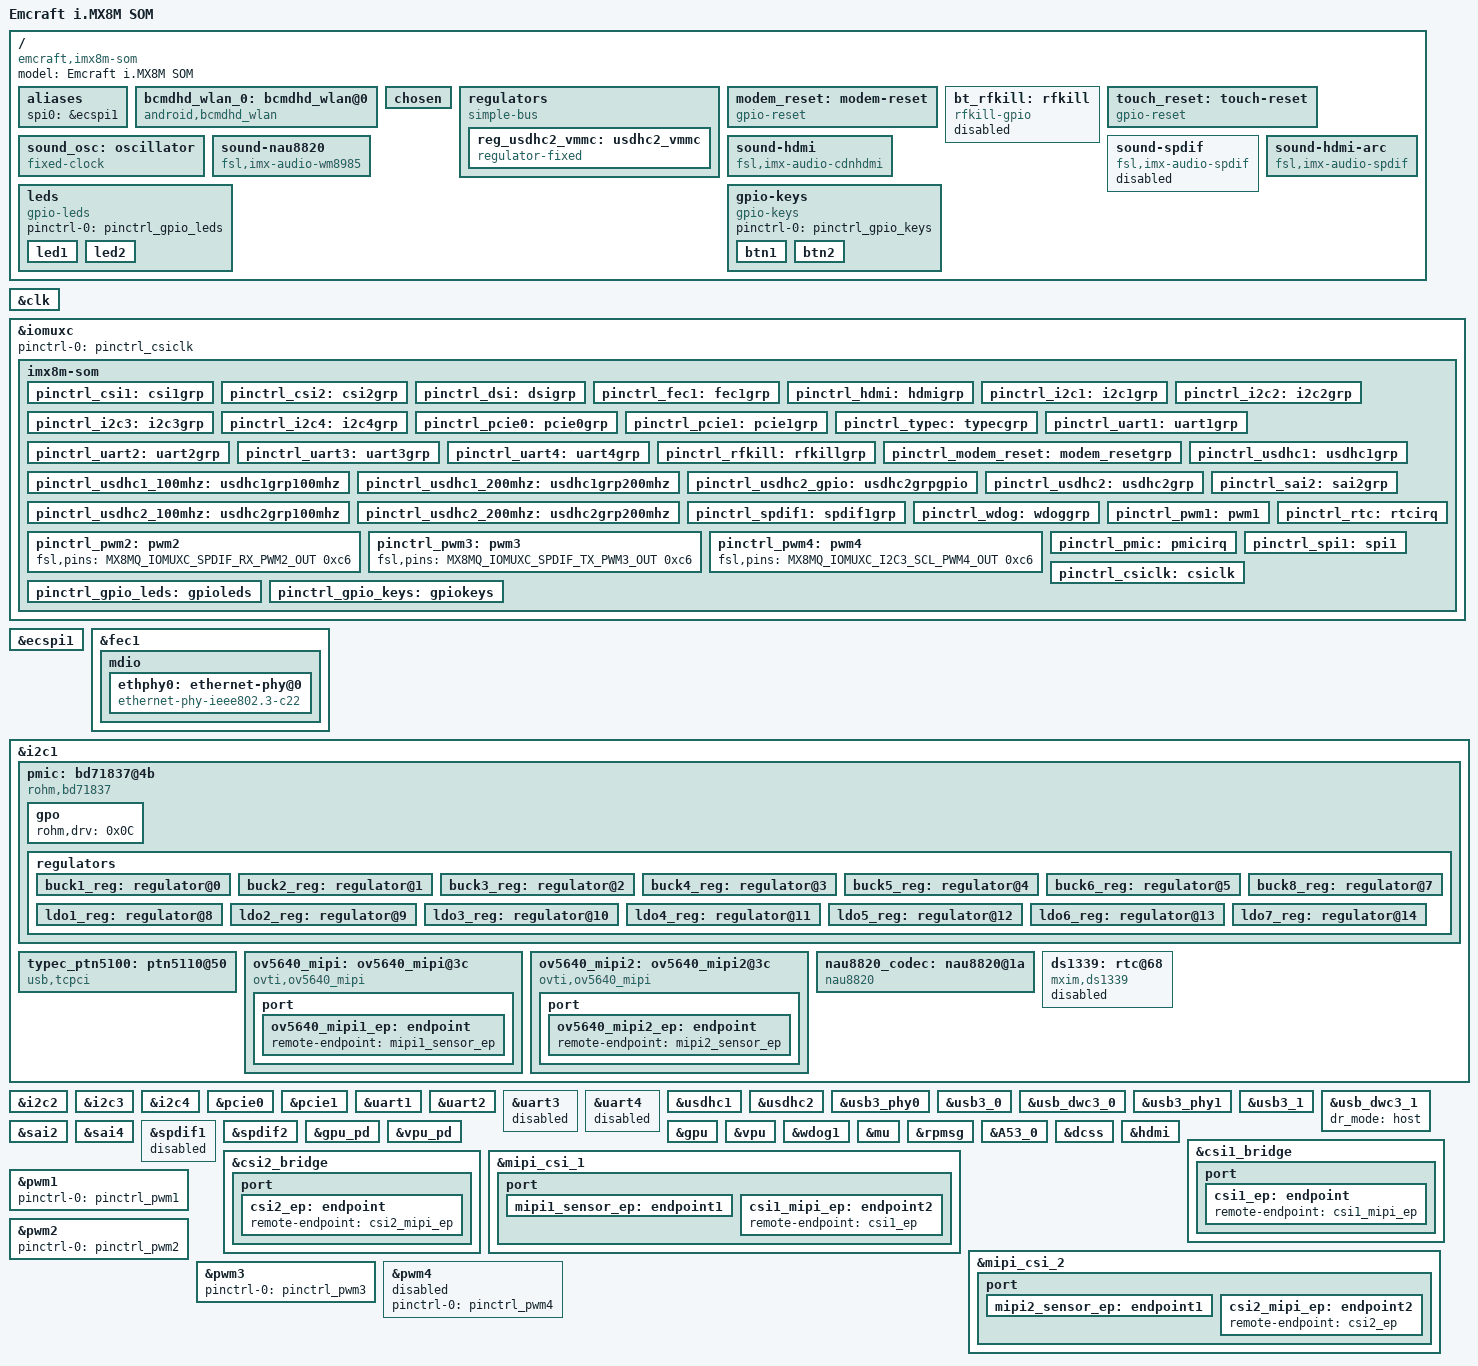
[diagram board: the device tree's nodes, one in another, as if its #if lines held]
/*
 * Copyright 2017 NXP
 *
 * This program is free software; you can redistribute it and/or
 * modify it under the terms of the GNU General Public License
 * as published by the Free Software Foundation; either version 2
 * of the License, or (at your option) any later version.
 *
 * This program is distributed in the hope that it will be useful,
 * but WITHOUT ANY WARRANTY; without even the implied warranty of
 * MERCHANTABILITY or FITNESS FOR A PARTICULAR PURPOSE.  See the
 * GNU General Public License for more details.
 */

/dts-v1/;

/*
 * Define this to support IMX8M-SOM-BSB with external PHY clock
 * #define PHY_USE_EXT25MHZ
 */

/*
 * Define this to enable i2c3 channel instead of pwm4 on IMX8M-SOM-BSB
 * #define I2C3_ENABLE
 */
#define I2C3_ENABLE

/*
 * Define this to enable camera on CSI2 channel instead of CSI1
 * #define CSI2_CAM_ENABLE
 */

#include "freescale/fsl-imx8mq.dtsi"

/ {
	model = "Emcraft i.MX8M SOM";
	compatible = "emcraft,imx8m-som", "fsl,imx8mq";

	aliases {
	    spi0 = &ecspi1;
	};

	bcmdhd_wlan_0: bcmdhd_wlan@0 {
		compatible = "android,bcmdhd_wlan";
		bcmdhd_fw = "/lib/firmware/bcm/1CX_BCM4356/fw_bcmdhd.bin";
		bcmdhd_nv = "/lib/firmware/bcm/1CX_BCM4356/bcmdhd.cal";
	};

	chosen {
		bootargs = "console=ttymxc0,115200 earlycon=ec_imx6q,0x30860000,115200";
		stdout-path = &uart1;
	};

	regulators {
		compatible = "simple-bus";
		#address-cells = <1>;
		#size-cells = <0>;

		reg_usdhc2_vmmc: usdhc2_vmmc {
			compatible = "regulator-fixed";
			regulator-name = "VSD_3V3";
			regulator-min-microvolt = <3300000>;
			regulator-max-microvolt = <3300000>;
			gpio = <&gpio2 19 GPIO_ACTIVE_HIGH>;
			enable-active-high;
		};
	};

	modem_reset: modem-reset {
		compatible = "gpio-reset";
		pinctrl-names = "default";
		pinctrl-0 = <&pinctrl_modem_reset>;
		reset-gpios = <&gpio3 6 GPIO_ACTIVE_LOW>;
		reset-delay-us = <2000>;
		reset-post-delay-ms = <40>;
		#reset-cells = <0>;
		status = "okay";
	};

	bt_rfkill: rfkill {
		compatible = "rfkill-gpio";
		pinctrl-names = "default";
		pinctrl-0 = <&pinctrl_rfkill>;
		type = "bluetooth";
		shutdown-gpios = <&gpio3 3 GPIO_ACTIVE_HIGH>;
		status = "disabled";
	};

	touch_reset: touch-reset {
		compatible = "gpio-reset";
		reset-gpios = <&gpio3 9 GPIO_ACTIVE_LOW>;
		reset-delay-us = <10000>;
		#reset-cells = <0>;
	};

	sound_osc: oscillator {
		compatible = "fixed-clock";
		#clock-cells = <1>;
		clock-frequency  = <12000000>;
		clock-output-names = "sound_osc";
	};

	sound-nau8820 {
		compatible = "fsl,imx-audio-wm8985";
		model = "nau8820-audio";
		audio-cpu = <&sai2>;
		audio-codec = <&nau8820_codec>;
	};

	sound-hdmi {
		compatible = "fsl,imx-audio-cdnhdmi";
		model = "imx-audio-hdmi";
		audio-cpu = <&sai4>;
		protocol = <1>;
	};

	sound-spdif {
		compatible = "fsl,imx-audio-spdif";
		model = "imx-spdif";
		spdif-controller = <&spdif1>;
		spdif-out;
		spdif-in;
		status = "disabled";
	};

	sound-hdmi-arc {
		compatible = "fsl,imx-audio-spdif";
		model = "imx-hdmi-arc";
		spdif-controller = <&spdif2>;
		spdif-in;
	};

	leds {
		compatible = "gpio-leds";
		pinctrl-names = "default";
		pinctrl-0 = <&pinctrl_gpio_leds>;
		status = "okay";

		led1 {
			label = "LED 1";
			gpios = <&gpio3 19 GPIO_ACTIVE_HIGH>;
			default-state = "off";
		};
		led2 {
			label = "LED 2";
			gpios = <&gpio1 13 GPIO_ACTIVE_HIGH>;
			default-state = "off";
		};
	};

	gpio-keys {
		compatible = "gpio-keys";
		pinctrl-names = "default";
		pinctrl-0 = <&pinctrl_gpio_keys>;

		btn1 {
			label = "BTN 1";
			gpios = <&gpio4 21 GPIO_ACTIVE_LOW>;
			gpio-key,wakeup;
			linux,code = <KEY_VOLUMEUP>;
		};
		btn2 {
			label = "BTN 2";
			gpios = <&gpio4 22 GPIO_ACTIVE_LOW>;
			gpio-key,wakeup;
			linux,code = <KEY_VOLUMEDOWN>;
		};
	};
};

&clk {
	assigned-clocks = <&clk IMX8MQ_AUDIO_PLL1>;
	assigned-clock-rates = <786432000>;
};

&iomuxc {
	pinctrl-names = "default";
	pinctrl-0 = <&pinctrl_csiclk>;

	imx8m-som {
		pinctrl_csi1: csi1grp {
			fsl,pins = <
				MX8MQ_IOMUXC_GPIO1_IO07_GPIO1_IO7		0x19
			>;
		};
		pinctrl_csi2: csi2grp {
			fsl,pins = <
				MX8MQ_IOMUXC_GPIO1_IO05_GPIO1_IO5		0x19
			>;
		};

		pinctrl_dsi: dsigrp {
			fsl,pins = <
				MX8MQ_IOMUXC_NAND_DATA07_GPIO3_IO13	0x16
			>;
		};

		pinctrl_fec1: fec1grp {
			fsl,pins = <
				MX8MQ_IOMUXC_ENET_MDC_ENET1_MDC		0x3
				MX8MQ_IOMUXC_ENET_MDIO_ENET1_MDIO	0x23
				MX8MQ_IOMUXC_ENET_TD3_ENET1_RGMII_TD3	0x1f
				MX8MQ_IOMUXC_ENET_TD2_ENET1_RGMII_TD2	0x1f
				MX8MQ_IOMUXC_ENET_TD1_ENET1_RGMII_TD1	0x1f
				MX8MQ_IOMUXC_ENET_TD0_ENET1_RGMII_TD0	0x1f
				MX8MQ_IOMUXC_ENET_RD3_ENET1_RGMII_RD3	0x91
				MX8MQ_IOMUXC_ENET_RD2_ENET1_RGMII_RD2	0x91
				MX8MQ_IOMUXC_ENET_RD1_ENET1_RGMII_RD1	0x91
				MX8MQ_IOMUXC_ENET_RD0_ENET1_RGMII_RD0	0x91
				MX8MQ_IOMUXC_ENET_TXC_ENET1_RGMII_TXC	0x1f
				MX8MQ_IOMUXC_ENET_RXC_ENET1_RGMII_RXC	0x91
				MX8MQ_IOMUXC_ENET_RX_CTL_ENET1_RGMII_RX_CTL	0x91
				MX8MQ_IOMUXC_ENET_TX_CTL_ENET1_RGMII_TX_CTL	0x1f
				MX8MQ_IOMUXC_GPIO1_IO09_GPIO1_IO9	0x19
				MX8MQ_IOMUXC_GPIO1_IO15_CCMSRCGPCMIX_CLKO2      0x1f
			>;
		};

		pinctrl_hdmi: hdmigrp {
			fsl,pins = <
				MX8MQ_IOMUXC_SAI3_MCLK_GPIO5_IO2	0x16
			>;
		};

		pinctrl_i2c1: i2c1grp {
			fsl,pins = <
				MX8MQ_IOMUXC_I2C1_SCL_I2C1_SCL			0x4000007f
				MX8MQ_IOMUXC_I2C1_SDA_I2C1_SDA			0x4000007f
			>;
		};

		pinctrl_i2c2: i2c2grp {
			fsl,pins = <
				MX8MQ_IOMUXC_I2C2_SCL_I2C2_SCL			0x4000007f
				MX8MQ_IOMUXC_I2C2_SDA_I2C2_SDA			0x4000007f
			>;
		};

		pinctrl_i2c3: i2c3grp {
			fsl,pins = <
				MX8MQ_IOMUXC_I2C3_SCL_I2C3_SCL			0x4000007f
				MX8MQ_IOMUXC_I2C3_SDA_I2C3_SDA			0x4000007f
				MX8MQ_IOMUXC_NAND_DATA02_GPIO3_IO8		0x17059	/* TOUCH INT */
				MX8MQ_IOMUXC_NAND_DATA03_GPIO3_IO9		0x16	/* TOUCH RST */
			>;
		};

		pinctrl_i2c4: i2c4grp {
			fsl,pins = <
				MX8MQ_IOMUXC_I2C4_SCL_I2C4_SCL			0x4000007f
				MX8MQ_IOMUXC_I2C4_SDA_I2C4_SDA			0x4000007f
			>;
		};


		pinctrl_pcie0: pcie0grp {
			fsl,pins = <
				MX8MQ_IOMUXC_NAND_RE_B_GPIO3_IO15	0x16
				MX8MQ_IOMUXC_NAND_DATA05_GPIO3_IO11	0x16
				MX8MQ_IOMUXC_NAND_DATA04_GPIO3_IO10	0x16
			>;
		};

		pinctrl_pcie1: pcie1grp {
			fsl,pins = <
				MX8MQ_IOMUXC_NAND_WP_B_GPIO3_IO18	0x16
				MX8MQ_IOMUXC_NAND_CLE_GPIO3_IO5	0x16
				MX8MQ_IOMUXC_NAND_WE_B_GPIO3_IO17	0x16
			>;
		};


		pinctrl_typec: typecgrp {
			fsl,pins = <
				MX8MQ_IOMUXC_NAND_DATA06_GPIO3_IO12	0x16
				MX8MQ_IOMUXC_NAND_CE0_B_GPIO3_IO1	0x17059
			>;
		};

		pinctrl_uart1: uart1grp {
			fsl,pins = <
				MX8MQ_IOMUXC_UART1_RXD_UART1_DCE_RX		0x49
				MX8MQ_IOMUXC_UART1_TXD_UART1_DCE_TX		0x49
			>;
		};

		pinctrl_uart2: uart2grp {
			fsl,pins = <
				MX8MQ_IOMUXC_UART2_TXD_UART2_DCE_TX		0x49
				MX8MQ_IOMUXC_UART2_RXD_UART2_DCE_RX		0x49
				MX8MQ_IOMUXC_UART4_RXD_UART2_DCE_CTS_B		0x49
				MX8MQ_IOMUXC_UART4_TXD_UART2_DCE_RTS_B		0x49
			>;
		};

		pinctrl_uart3: uart3grp {
			fsl,pins = <
				MX8MQ_IOMUXC_UART3_RXD_UART3_DCE_RX		0x49
				MX8MQ_IOMUXC_UART3_TXD_UART3_DCE_TX		0x49
			>;
		};

		pinctrl_uart4: uart4grp {
			fsl,pins = <
				MX8MQ_IOMUXC_ECSPI2_SCLK_UART4_DCE_RX		0x49
				MX8MQ_IOMUXC_ECSPI2_MOSI_UART4_DCE_TX		0x49
				MX8MQ_IOMUXC_ECSPI2_MISO_UART4_DCE_CTS_B	0x49
				MX8MQ_IOMUXC_ECSPI2_SS0_UART4_DCE_RTS_B		0x49
				MX8MQ_IOMUXC_GPIO1_IO00_ANAMIX_REF_CLK_32K	0x49
			>;
		};

		pinctrl_rfkill: rfkillgrp {
			fsl,pins = <
				/* BT_RF_KILL */
				MX8MQ_IOMUXC_NAND_CE2_B_GPIO3_IO3		0x19
			>;
		};

		pinctrl_modem_reset: modem_resetgrp {
			fsl,pins = <
				/* BT_REG_ON */
				MX8MQ_IOMUXC_NAND_DATA00_GPIO3_IO6		0x19
			>;
		};

		pinctrl_usdhc1: usdhc1grp {
			fsl,pins = <
				MX8MQ_IOMUXC_SD1_CLK_USDHC1_CLK			0x83
				MX8MQ_IOMUXC_SD1_CMD_USDHC1_CMD			0xc3
				MX8MQ_IOMUXC_SD1_DATA0_USDHC1_DATA0		0xc3
				MX8MQ_IOMUXC_SD1_DATA1_USDHC1_DATA1		0xc3
				MX8MQ_IOMUXC_SD1_DATA2_USDHC1_DATA2		0xc3
				MX8MQ_IOMUXC_SD1_DATA3_USDHC1_DATA3		0xc3
				MX8MQ_IOMUXC_SD1_DATA4_USDHC1_DATA4		0xc3
				MX8MQ_IOMUXC_SD1_DATA5_USDHC1_DATA5		0xc3
				MX8MQ_IOMUXC_SD1_DATA6_USDHC1_DATA6		0xc3
				MX8MQ_IOMUXC_SD1_DATA7_USDHC1_DATA7		0xc3
				MX8MQ_IOMUXC_SD1_STROBE_USDHC1_STROBE		0x83
				MX8MQ_IOMUXC_SD1_RESET_B_USDHC1_RESET_B		0xc1
			>;
		};

		pinctrl_usdhc1_100mhz: usdhc1grp100mhz {
			fsl,pins = <
				MX8MQ_IOMUXC_SD1_CLK_USDHC1_CLK			0x85
				MX8MQ_IOMUXC_SD1_CMD_USDHC1_CMD			0xc5
				MX8MQ_IOMUXC_SD1_DATA0_USDHC1_DATA0		0xc5
				MX8MQ_IOMUXC_SD1_DATA1_USDHC1_DATA1		0xc5
				MX8MQ_IOMUXC_SD1_DATA2_USDHC1_DATA2		0xc5
				MX8MQ_IOMUXC_SD1_DATA3_USDHC1_DATA3		0xc5
				MX8MQ_IOMUXC_SD1_DATA4_USDHC1_DATA4		0xc5
				MX8MQ_IOMUXC_SD1_DATA5_USDHC1_DATA5		0xc5
				MX8MQ_IOMUXC_SD1_DATA6_USDHC1_DATA6		0xc5
				MX8MQ_IOMUXC_SD1_DATA7_USDHC1_DATA7		0xc5
				MX8MQ_IOMUXC_SD1_STROBE_USDHC1_STROBE		0x85
				MX8MQ_IOMUXC_SD1_RESET_B_USDHC1_RESET_B		0xc1
			>;
		};

		pinctrl_usdhc1_200mhz: usdhc1grp200mhz {
			fsl,pins = <
				MX8MQ_IOMUXC_SD1_CLK_USDHC1_CLK			0x87
				MX8MQ_IOMUXC_SD1_CMD_USDHC1_CMD			0xc7
				MX8MQ_IOMUXC_SD1_DATA0_USDHC1_DATA0		0xc7
				MX8MQ_IOMUXC_SD1_DATA1_USDHC1_DATA1		0xc7
				MX8MQ_IOMUXC_SD1_DATA2_USDHC1_DATA2		0xc7
				MX8MQ_IOMUXC_SD1_DATA3_USDHC1_DATA3		0xc7
				MX8MQ_IOMUXC_SD1_DATA4_USDHC1_DATA4		0xc7
				MX8MQ_IOMUXC_SD1_DATA5_USDHC1_DATA5		0xc7
				MX8MQ_IOMUXC_SD1_DATA6_USDHC1_DATA6		0xc7
				MX8MQ_IOMUXC_SD1_DATA7_USDHC1_DATA7		0xc7
				MX8MQ_IOMUXC_SD1_STROBE_USDHC1_STROBE		0x87
				MX8MQ_IOMUXC_SD1_RESET_B_USDHC1_RESET_B		0xc1
			>;
		};

		pinctrl_usdhc2_gpio: usdhc2grpgpio {
			fsl,pins = <
				MX8MQ_IOMUXC_SD2_CD_B_GPIO2_IO12	0x41
				MX8MQ_IOMUXC_SD2_RESET_B_GPIO2_IO19	0x41
			>;
		};

		pinctrl_usdhc2: usdhc2grp {
			fsl,pins = <
				MX8MQ_IOMUXC_SD2_CLK_USDHC2_CLK			0x83
				MX8MQ_IOMUXC_SD2_CMD_USDHC2_CMD			0xc3
				MX8MQ_IOMUXC_SD2_DATA0_USDHC2_DATA0		0xc3
				MX8MQ_IOMUXC_SD2_DATA1_USDHC2_DATA1		0xc3
				MX8MQ_IOMUXC_SD2_DATA2_USDHC2_DATA2		0xc3
				MX8MQ_IOMUXC_SD2_DATA3_USDHC2_DATA3		0xc3
				MX8MQ_IOMUXC_GPIO1_IO04_USDHC2_VSELECT		0xc1
			>;
		};

		pinctrl_usdhc2_100mhz: usdhc2grp100mhz {
			fsl,pins = <
				MX8MQ_IOMUXC_SD2_CLK_USDHC2_CLK			0x85
				MX8MQ_IOMUXC_SD2_CMD_USDHC2_CMD			0xc5
				MX8MQ_IOMUXC_SD2_DATA0_USDHC2_DATA0		0xc5
				MX8MQ_IOMUXC_SD2_DATA1_USDHC2_DATA1		0xc5
				MX8MQ_IOMUXC_SD2_DATA2_USDHC2_DATA2		0xc5
				MX8MQ_IOMUXC_SD2_DATA3_USDHC2_DATA3		0xc5
				MX8MQ_IOMUXC_GPIO1_IO04_USDHC2_VSELECT		0xc1
			>;
		};

		pinctrl_usdhc2_200mhz: usdhc2grp200mhz {
			fsl,pins = <
				MX8MQ_IOMUXC_SD2_CLK_USDHC2_CLK			0x87
				MX8MQ_IOMUXC_SD2_CMD_USDHC2_CMD			0xc7
				MX8MQ_IOMUXC_SD2_DATA0_USDHC2_DATA0		0xc7
				MX8MQ_IOMUXC_SD2_DATA1_USDHC2_DATA1		0xc7
				MX8MQ_IOMUXC_SD2_DATA2_USDHC2_DATA2		0xc7
				MX8MQ_IOMUXC_SD2_DATA3_USDHC2_DATA3		0xc7
				MX8MQ_IOMUXC_GPIO1_IO04_USDHC2_VSELECT		0xc1
			>;
		};

		pinctrl_sai2: sai2grp {
			fsl,pins = <
				MX8MQ_IOMUXC_SAI2_TXFS_SAI2_TX_SYNC	0xd6
				MX8MQ_IOMUXC_SAI2_TXC_SAI2_TX_BCLK	0xd6
				MX8MQ_IOMUXC_SAI2_TXD0_SAI2_TX_DATA0	0xd6
				MX8MQ_IOMUXC_SAI2_RXD0_SAI2_RX_DATA0	0xd6
			>;
		};

		pinctrl_spdif1: spdif1grp {
			fsl,pins = <
				MX8MQ_IOMUXC_SPDIF_TX_SPDIF1_OUT	0xd6
				MX8MQ_IOMUXC_SPDIF_RX_SPDIF1_IN		0xd6
			>;
		};

		pinctrl_wdog: wdoggrp {
			fsl,pins = <
				MX8MQ_IOMUXC_GPIO1_IO02_WDOG1_WDOG_B 0xc6
			>;
		};

		pinctrl_pwm1: pwm1 {
			fsl,pins = <
				MX8MQ_IOMUXC_SPDIF_EXT_CLK_PWM1_OUT 0xc6
			>;
		};

		pinctrl_pwm2: pwm2 {
			fsl,pins = <
				MX8MQ_IOMUXC_SPDIF_RX_PWM2_OUT 0xc6
			>;
		};

		pinctrl_pwm3: pwm3 {
			fsl,pins = <
				MX8MQ_IOMUXC_SPDIF_TX_PWM3_OUT 0xc6
			>;
		};

		pinctrl_pwm4: pwm4 {
			fsl,pins = <
				MX8MQ_IOMUXC_I2C3_SCL_PWM4_OUT 0xc6
			>;
		};

		pinctrl_pmic: pmicirq {
			fsl,pins = <
				MX8MQ_IOMUXC_GPIO1_IO12_GPIO1_IO12	0x41 /*0x17059*/
			>;
		};

		pinctrl_rtc: rtcirq {
			fsl,pins = <
				MX8MQ_IOMUXC_SAI3_RXC_GPIO4_IO29	0xC6
			>;
		};

		pinctrl_spi1: spi1 {
			fsl,pins = <
				MX8MQ_IOMUXC_ECSPI1_SCLK_ECSPI1_SCLK	0x0f
				MX8MQ_IOMUXC_ECSPI1_MOSI_ECSPI1_MOSI	0x0f
				MX8MQ_IOMUXC_ECSPI1_MISO_ECSPI1_MISO	0x0f
				MX8MQ_IOMUXC_ECSPI1_SS0_GPIO5_IO9	0x09
				MX8MQ_IOMUXC_NAND_CE1_B_GPIO3_IO2	0x09
			>;
		};

		pinctrl_csiclk: csiclk {
			fsl,pins = <
				MX8MQ_IOMUXC_GPIO1_IO14_CCMSRCGPCMIX_CLKO1	0x59
			>;
		};

		pinctrl_gpio_leds: gpioleds {
			fsl,pins = <
				MX8MQ_IOMUXC_SAI5_RXFS_GPIO3_IO19	0x16
				MX8MQ_IOMUXC_GPIO1_IO13_GPIO1_IO13	0x16
			>;
		};

		pinctrl_gpio_keys: gpiokeys {
			fsl,pins = <
				MX8MQ_IOMUXC_SAI2_RXFS_GPIO4_IO21	0x16
				MX8MQ_IOMUXC_SAI2_RXC_GPIO4_IO22	0x16
			>;
		};
	};
};

&ecspi1 {
	pinctrl-names = "default";
	pinctrl-0 = <&pinctrl_spi1>;
	status = "okay";
	cs-gpios = <&gpio5 9 GPIO_ACTIVE_LOW>, <&gpio3 2 GPIO_ACTIVE_LOW>;
	#address-cells = <1>;
	#size-cells = <0>;
};

&fec1 {
	pinctrl-names = "default";
	pinctrl-0 = <&pinctrl_fec1>;
	phy-mode = "rgmii-id";
	phy-handle = <&ethphy0>;
	fsl,magic-packet;
	status = "okay";

#ifdef PHY_USE_EXT25MHZ
	/* Removed "enet_phy_out" */
	clock-names = "ipg", "ahb", "ptp",
		    "enet_clk_ref", "enet_out";
#endif
	mdio {
		#address-cells = <1>;
		#size-cells = <0>;

		ethphy0: ethernet-phy@0 {
			compatible = "ethernet-phy-ieee802.3-c22";
			reg = <1>;
			at803x,led-act-blind-workaround;
			at803x,eee-disabled;
		};
	};
};

&i2c1 {
	clock-frequency = <100000>;
	pinctrl-names = "default";
	pinctrl-0 = <&pinctrl_i2c1>;
	status = "okay";

	pmic: bd71837@4b {
		reg = <0x4b>;
		compatible = "rohm,bd71837";
		/* PMIC BD71837 PMIC_nINT GPIO1_IO12 */
		pinctrl-0 = <&pinctrl_pmic>;
		gpio_intr = <&gpio1 12 GPIO_ACTIVE_LOW>;

		bd71837,pmic-buck1-uses-i2c-dvs;
		bd71837,pmic-buck1-dvs-voltage = <900000>, <850000>, <800000>; /* VDD_SOC: Run-Idle-Suspend */
		bd71837,pmic-buck2-uses-i2c-dvs;
		bd71837,pmic-buck2-dvs-voltage = <1000000>, <900000>, <0>; /* VDD_ARM: Run-Idle */
		bd71837,pmic-buck3-uses-i2c-dvs;
		bd71837,pmic-buck3-dvs-voltage = <1000000>, <0>, <0>; /* VDD_GPU: Run */
		bd71837,pmic-buck4-uses-i2c-dvs;
		bd71837,pmic-buck4-dvs-voltage = <1000000>, <0>, <0>; /* VDD_VPU: Run */

		gpo {
			rohm,drv = <0x0C>;	/* 0b0000_1100 all gpos with cmos output mode */
		};

		regulators {
			#address-cells = <1>;
			#size-cells = <0>;

			buck1_reg: regulator@0 {
				reg = <0>;
				regulator-compatible = "buck1";
				regulator-min-microvolt = <700000>;
				regulator-max-microvolt = <1300000>;
				regulator-boot-on;
				regulator-always-on;
				regulator-ramp-delay = <1250>;
			};

			buck2_reg: regulator@1 {
				reg = <1>;
				regulator-compatible = "buck2";
				regulator-min-microvolt = <700000>;
				regulator-max-microvolt = <1300000>;
				regulator-boot-on;
				regulator-always-on;
				regulator-ramp-delay = <1250>;
			};

			buck3_reg: regulator@2 {
				reg = <2>;
				regulator-compatible = "buck3";
				regulator-min-microvolt = <700000>;
				regulator-max-microvolt = <1300000>;
				regulator-boot-on;
				regulator-always-on;
			};

			buck4_reg: regulator@3 {
				reg = <3>;
				regulator-compatible = "buck4";
				regulator-min-microvolt = <700000>;
				regulator-max-microvolt = <1300000>;
				regulator-boot-on;
				regulator-always-on;
			};

			buck5_reg: regulator@4 {
				reg = <4>;
				regulator-compatible = "buck5";
				regulator-min-microvolt = <700000>;
				regulator-max-microvolt = <1350000>;
				regulator-boot-on;
				regulator-always-on;
			};

			buck6_reg: regulator@5 {
				reg = <5>;
				regulator-compatible = "buck6";
				regulator-min-microvolt = <3000000>;
				regulator-max-microvolt = <3300000>;
				regulator-boot-on;
				regulator-always-on;
			};
#if 0
			buck7_reg: regulator@6 {
				reg = <6>;
				regulator-compatible = "buck7";
				regulator-min-microvolt = <1605000>;
				regulator-max-microvolt = <1995000>;
				regulator-boot-on;
				regulator-always-on;
			};
#endif
			buck8_reg: regulator@7 {
				reg = <7>;
				regulator-compatible = "buck8";
				regulator-min-microvolt = <800000>;
				regulator-max-microvolt = <1400000>;
				regulator-boot-on;
				regulator-always-on;
			};

			ldo1_reg: regulator@8 {
				reg = <8>;
				regulator-compatible = "ldo1";
				regulator-min-microvolt = <3000000>;
				regulator-max-microvolt = <3300000>;
				regulator-boot-on;
				regulator-always-on;
			};

			ldo2_reg: regulator@9 {
				reg = <9>;
				regulator-compatible = "ldo2";
				regulator-min-microvolt = <900000>;
				regulator-max-microvolt = <900000>;
				regulator-boot-on;
				regulator-always-on;
			};

			ldo3_reg: regulator@10 {
				reg = <10>;
				regulator-compatible = "ldo3";
				regulator-min-microvolt = <1800000>;
				regulator-max-microvolt = <3300000>;
				regulator-boot-on;
				regulator-always-on;
			};

			ldo4_reg: regulator@11 {
				reg = <11>;
				regulator-compatible = "ldo4";
				regulator-min-microvolt = <900000>;
				regulator-max-microvolt = <1800000>;
				regulator-boot-on;
				regulator-always-on;
			};

			ldo5_reg: regulator@12 {
				reg = <12>;
				regulator-compatible = "ldo5";
				regulator-min-microvolt = <1800000>;
				regulator-max-microvolt = <3300000>;
				regulator-boot-on;
				regulator-always-on;
			};

			ldo6_reg: regulator@13 {
				reg = <13>;
				regulator-compatible = "ldo6";
				regulator-min-microvolt = <900000>;
				regulator-max-microvolt = <1800000>;
				regulator-boot-on;
				regulator-always-on;
			};

			ldo7_reg: regulator@14 {
				reg = <14>;
				regulator-compatible = "ldo7";
				regulator-min-microvolt = <1800000>;
				regulator-max-microvolt = <3300000>;
				regulator-boot-on;
				regulator-always-on;
			};
		};
	};

	typec_ptn5100: ptn5110@50 {
		compatible = "usb,tcpci";
		pinctrl-names = "default";
		pinctrl-0 = <&pinctrl_typec>;
		reg = <0x52>;
		interrupt-parent = <&gpio3>;
		interrupts = <1 IRQ_TYPE_LEVEL_LOW>;
		ss-sel-gpios = <&gpio3 12 GPIO_ACTIVE_HIGH>;
		src-pdos = <0x380190c8>;
		snk-pdos = <0x380190c8 0x3802d0c8>;
		max-snk-mv = <9000>;
		max-snk-ma = <1000>;
		max-snk-mw = <9000>;
		op-snk-mw = <9000>;
		port-type = "drp";
		default-role = "sink";
	};

	ov5640_mipi: ov5640_mipi@3c {
		compatible = "ovti,ov5640_mipi";
		reg = <0x3c>;
#ifndef CSI2_CAM_ENABLE
		status = "okay";
#else
		status = "disabled";
#endif
		pinctrl-names = "default";
		pinctrl-0 = <&pinctrl_csi1>;
		clocks = <&clk IMX8MQ_CLK_CLKO1_DIV>;
		clock-names = "csi_mclk";
		assigned-clocks = <&clk IMX8MQ_CLK_CLKO1_SRC>,
				  <&clk IMX8MQ_CLK_CLKO1_DIV>;
		assigned-clock-parents = <&clk IMX8MQ_SYS1_PLL_200M>;
		assigned-clock-rates = <0>, <20000000>;
		csi_id = <0>;
		pwn-gpios = <&gpio1 7 GPIO_ACTIVE_LOW>;
		mclk = <20000000>;
		mclk_source = <0>;
		port {
			ov5640_mipi1_ep: endpoint {
				remote-endpoint = <&mipi1_sensor_ep>;
			};
		};
	};

	ov5640_mipi2: ov5640_mipi2@3c {
		compatible = "ovti,ov5640_mipi";
		reg = <0x3c>;
#ifdef CSI2_CAM_ENABLE
		status = "okay";
#else
		status = "disabled";
#endif
		pinctrl-names = "default";
		pinctrl-0 = <&pinctrl_csi2>;
		clocks = <&clk IMX8MQ_CLK_CLKO1_DIV>;
		clock-names = "csi_mclk";
		assigned-clocks = <&clk IMX8MQ_CLK_CLKO1_SRC>,
				  <&clk IMX8MQ_CLK_CLKO1_DIV>;
		assigned-clock-parents = <&clk IMX8MQ_SYS1_PLL_200M>;
		assigned-clock-rates = <0>, <20000000>;
		csi_id = <0>;
		pwn-gpios = <&gpio1 5 GPIO_ACTIVE_LOW>;
		mclk = <20000000>;
		mclk_source = <0>;
		port {
			ov5640_mipi2_ep: endpoint {
				remote-endpoint = <&mipi2_sensor_ep>;
			};
		};
	};

	nau8820_codec: nau8820@1a {
		#sound-dai-cells = <0>;
		compatible = "nau8820";
		reg = <0x1a>;
		clocks = <&sound_osc 0>;
	};

	ds1339: rtc@68 {
		compatible = "mxim,ds1339";
		reg = <0x68>;
		/* RTC DS1339U-33+ nIRQ GPIO4_IO29 */
		pinctrl-0 = <&pinctrl_rtc>;
		interrupt-parent = <&gpio4>;
		interrupts = <29 IRQ_TYPE_EDGE_FALLING>;
		status = "disabled";
	};
};

&i2c2 {
	clock-frequency = <100000>;
	pinctrl-names = "default";
	pinctrl-0 = <&pinctrl_i2c2>;
	status = "okay";
};

&i2c3 {
	clock-frequency = <100000>;
	pinctrl-names = "default";
	pinctrl-0 = <&pinctrl_i2c3>;
#ifdef I2C3_ENABLE
	status = "okay";
#else
	status = "disabled";
#endif
};

&i2c4 {
	clock-frequency = <100000>;
	pinctrl-names = "default";
	pinctrl-0 = <&pinctrl_i2c4>;
	status = "okay";
};

&pcie0{
	pinctrl-names = "default";
	pinctrl-0 = <&pinctrl_pcie0>;
	clkreq-gpio = <&gpio3 15 GPIO_ACTIVE_LOW>;
	disable-gpio = <&gpio3 11 GPIO_ACTIVE_LOW>;
	reset-gpio = <&gpio3 10 GPIO_ACTIVE_LOW>;
	ext_osc = <1>;
	hard-wired = <1>;
	clk2-gen;
	status = "okay";
};

&pcie1{
	pinctrl-names = "default";
	pinctrl-0 = <&pinctrl_pcie1>;
	clkreq-gpio = <&gpio3 18 GPIO_ACTIVE_LOW>;
	disable-gpio = <&gpio3 5 GPIO_ACTIVE_LOW>;
	reset-gpio = <&gpio3 17 GPIO_ACTIVE_LOW>;
	ext_osc = <1>;
	status = "okay";
};

&uart1 { /* console */
	pinctrl-names = "default";
	pinctrl-0 = <&pinctrl_uart1>;
	assigned-clocks = <&clk IMX8MQ_CLK_UART1_SRC>;
	assigned-clock-parents = <&clk IMX8MQ_CLK_25M>;
	status = "okay";
};

&uart2 { /* BT */
	pinctrl-names = "default";
	pinctrl-0 = <&pinctrl_uart2>;
	assigned-clocks = <&clk IMX8MQ_CLK_UART2_SRC>;
	assigned-clock-parents = <&clk IMX8MQ_SYS1_PLL_80M>;
	fsl,uart-has-rtscts;
	resets = <&modem_reset>;
	status = "okay";
};

&uart3 {
	pinctrl-names = "default";
	pinctrl-0 = <&pinctrl_uart3>;
	assigned-clocks = <&clk IMX8MQ_CLK_UART3_SRC>;
	assigned-clock-parents = <&clk IMX8MQ_CLK_25M>;
	status = "disabled";
};

&uart4 {
	pinctrl-names = "default";
	pinctrl-0 = <&pinctrl_uart4>;
	assigned-clocks = <&clk IMX8MQ_CLK_UART4_SRC>;
	assigned-clock-parents = <&clk IMX8MQ_CLK_25M>;
	fsl,uart-has-rtscts;
	resets = <&modem_reset>;
	status = "disabled";
};

&usdhc1 {
	pinctrl-names = "default", "state_100mhz", "state_200mhz";
	pinctrl-0 = <&pinctrl_usdhc1>;
	pinctrl-1 = <&pinctrl_usdhc1_100mhz>;
	pinctrl-2 = <&pinctrl_usdhc1_200mhz>;
	bus-width = <8>;
	non-removable;
	status = "okay";
};

&usdhc2 {
	pinctrl-names = "default", "state_100mhz", "state_200mhz";
	pinctrl-0 = <&pinctrl_usdhc2>, <&pinctrl_usdhc2_gpio>;
	pinctrl-1 = <&pinctrl_usdhc2_100mhz>, <&pinctrl_usdhc2_gpio>;
	pinctrl-2 = <&pinctrl_usdhc2_200mhz>, <&pinctrl_usdhc2_gpio>;
	bus-width = <4>;
	cd-gpios = <&gpio2 12 GPIO_ACTIVE_LOW>;
	vmmc-supply = <&reg_usdhc2_vmmc>;
	status = "okay";
};

&usb3_phy0 {
	status = "okay";
};

&usb3_0 {
	status = "okay";
};

&usb_dwc3_0 {
	status = "okay";
	extcon = <&typec_ptn5100>;
	dr_mode = "otg";
};

&usb3_phy1 {
	status = "okay";
};

&usb3_1 {
	status = "okay";
};

&usb_dwc3_1 {
	status = "okay";
	dr_mode = "host";
};

&sai2 {
	pinctrl-names = "default";
	pinctrl-0 = <&pinctrl_sai2>;

	clocks = <&clk IMX8MQ_CLK_SAI2_IPG>;
	clock-names = "bus";

	status = "okay";
};

&sai4 {
	assigned-clocks = <&clk IMX8MQ_CLK_SAI4_SRC>,
			<&clk IMX8MQ_CLK_SAI4_DIV>;
	assigned-clock-parents = <&clk IMX8MQ_AUDIO_PLL1_OUT>;
	assigned-clock-rates = <0>, <24576000>;
	status = "okay";
};

&spdif1 {
	pinctrl-names = "default";
	pinctrl-0 = <&pinctrl_spdif1>;
	assigned-clocks = <&clk IMX8MQ_CLK_SPDIF1_SRC>,
			<&clk IMX8MQ_CLK_SPDIF1_DIV>;
	assigned-clock-parents = <&clk IMX8MQ_AUDIO_PLL1_OUT>;
	assigned-clock-rates = <0>, <24576000>;
	status = "disabled";
};

&spdif2 {
	assigned-clocks = <&clk IMX8MQ_CLK_SPDIF2_SRC>,
			<&clk IMX8MQ_CLK_SPDIF2_DIV>;
	assigned-clock-parents = <&clk IMX8MQ_AUDIO_PLL1_OUT>;
	assigned-clock-rates = <0>, <24576000>;
	status = "okay";
};

&gpu_pd {
// TBD: define correct power supply
//	power-supply = <&sw1a_reg>;
};

&vpu_pd {
// TBD: define correct power supply
//	power-supply = <&sw1c_reg>;
};

&gpu {
	status = "okay";
};

&vpu {
	status = "okay";
};

&wdog1 {
	pinctrl-names = "default";
	pinctrl-0 = <&pinctrl_wdog>;
	fsl,ext-reset-output;
	status = "okay";
};

&mu {
	status = "okay";
};

&rpmsg{
	/*
	 * 64K for one rpmsg instance:
	 * --0xb8000000~0xb800ffff: pingpong
	 */
	vdev-nums = <1>;
	reg = <0x0 0x58000000 0x0 0x10000>;
	status = "okay";
};

&A53_0 {
	operating-points = <
		/* kHz    uV */
		1500000 1000000
		1300000 1000000
		1000000 900000
		800000  900000
	>;
	dc-supply = <&buck2_reg>;
};

&dcss {
	status = "okay";

#ifndef MIPI_DSI_ENABLE
	disp-dev = "hdmi_disp";
	disp-mode = <5>;
#else
	disp-dev = "mipi_disp";
	assigned-clocks = <&clk IMX8MQ_CLK_DISP_AXI_SRC>,
			  <&clk IMX8MQ_CLK_DISP_APB_SRC>,
			  <&clk IMX8MQ_CLK_DISP_RTRM_SRC>,
			  <&clk IMX8MQ_CLK_DISP_RTRM_PRE_DIV>,
			  <&clk IMX8MQ_CLK_DC_PIXEL_SRC>,
			  <&clk IMX8MQ_VIDEO_PLL1_REF_SEL>,
			  <&clk IMX8MQ_VIDEO_PLL1>;

	assigned-clock-parents = <&clk IMX8MQ_SYS1_PLL_800M>,
				 <&clk IMX8MQ_SYS2_PLL_125M>,
				 <&clk IMX8MQ_SYS1_PLL_800M>,
				 <&clk IMX8MQ_CLK_DISP_RTRM_CG>,
				 <&clk IMX8MQ_VIDEO_PLL1_OUT>,
				 <&clk IMX8MQ_CLK_25M>;
	assigned-clock-rates = <800000000>,
			       <125000000>,
			       <400000000>,
			       <400000000>,
			       <120000000>,
			       <0>,
			       <599999999>;
	dcss_disp0: port@0 {
		reg = <0>;
		dcss_disp0_mipi_dsi: mipi_dsi {
			remote-endpoint = <&mipi_dsi_in>;
		};
	};
#endif
};

#ifndef MIPI_DSI_ENABLE
&hdmi {
	status = "okay";
};

#else

&mipi_dsi_phy {
	status = "okay";
};

&mipi_dsi {
	status = "okay";

	pinctrl-names = "default";
	pinctrl-0 = <&pinctrl_dsi>;
	reset-gpios = <&gpio3 13 GPIO_ACTIVE_LOW>;

	assigned-clocks = <&clk IMX8MQ_CLK_DSI_PHY_REF_SRC>,
			  <&clk IMX8MQ_CLK_DSI_CORE_SRC>,
			  <&clk IMX8MQ_VIDEO_PLL1_REF_SEL>,
			  <&clk IMX8MQ_VIDEO_PLL1>;
	assigned-clock-parents = <&clk IMX8MQ_VIDEO_PLL1_OUT>,
				 <&clk IMX8MQ_SYS1_PLL_266M>,
				 <&clk IMX8MQ_CLK_25M>;
	assigned-clock-rates = <24000000>,
			       <266000000>,
			       <0>,
			       <599999999>;
	port@1 {
		mipi_dsi_in: endpoint {
			remote-endpoint = <&dcss_disp0_mipi_dsi>;
		};
	};
};

&mipi_dsi_bridge {
	status = "okay";
	panel@0 {
		compatible = "orisetech,otm8009a";
		reg = <0>;
		port {
			panel1_in: endpoint {
				remote-endpoint = <&mipi_dsi_bridge_out>;
			};
		};
	};
	port@1 {
		mipi_dsi_bridge_out: endpoint {
			remote-endpoint = <&panel1_in>;
		};
	};
};
#endif /* MIPI_DSI_ENABLE */

&csi1_bridge {
	fsl,mipi-mode;
	fsl,two-8bit-sensor-mode;
	status = "okay";

	port {
		csi1_ep: endpoint {
			remote-endpoint = <&csi1_mipi_ep>;
		};
	};
};

&csi2_bridge {
	fsl,mipi-mode;
	fsl,two-8bit-sensor-mode;
	status = "okay";

	port {
		csi2_ep: endpoint {
			remote-endpoint = <&csi2_mipi_ep>;
		};
	};
};

&mipi_csi_1 {
	#address-cells = <1>;
	#size-cells = <0>;
	status = "okay";
	port {
		mipi1_sensor_ep: endpoint1 {
			remote-endpoint = <&ov5640_mipi1_ep>;
			data-lanes = <1 2>;
		};

		csi1_mipi_ep: endpoint2 {
			remote-endpoint = <&csi1_ep>;
		};
	};
};

&mipi_csi_2 {
	#address-cells = <1>;
	#size-cells = <0>;
	status = "okay";
	port {
		mipi2_sensor_ep: endpoint1 {
			remote-endpoint = <&ov5640_mipi2_ep>;
			data-lanes = <1 2>;
		};

		csi2_mipi_ep: endpoint2 {
			remote-endpoint = <&csi2_ep>;
		};
	};
};

&pwm1 {
	pinctrl-names = "default";
	pinctrl-0 = <&pinctrl_pwm1>;
	status = "okay";
};

&pwm2 {
	pinctrl-names = "default";
	pinctrl-0 = <&pinctrl_pwm2>;
	status = "okay";
};

&pwm3 {
	pinctrl-names = "default";
	pinctrl-0 = <&pinctrl_pwm3>;
	status = "okay";
};

&pwm4 {
	pinctrl-names = "default";
	pinctrl-0 = <&pinctrl_pwm4>;
#ifdef I2C3_ENABLE
	status = "disabled";
#else
	status = "okay";
#endif
};

